AUTOSAR XML (schema 4-2-2)
package /ARPackage_4
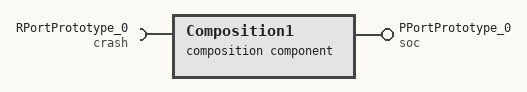
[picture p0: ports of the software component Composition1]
  composition sw component type Composition1
    provide port PPortPrototype_0: provided-interface=soc
    require port RPortPrototype_0: required-interface=crash
    4 x component:
      CPT_swc: type=swc
      CPT_ComM: type=ComM
      CPT_BswM: type=BswM
      CPT_EcuM: type=EcuM
    delegate CPT_swc.PPortPrototype_0 <-> outer port PPortPrototype_0
    delegate CPT_swc.RPortPrototype_0 <-> outer port RPortPrototype_0
